# AASRC0_CFG register map
Vendor: Texas Instruments
Peripheral module from a debugger description file (folder J7ES).
Registers are 32-bit, access per field, reset values left out (the file's numbers can be read two ways) unless marked. A register's access mark holds for its fields unless they carry their own. Offsets are as the file gives them; lines under a group give offsets from that group; [hi:lo] are bit positions; {n}, {i} and the like mark numbered series; 'fields as' and 'values as' point back to an identical list; <NAME> marks a mode.

## AASRC0_CFG
0x00 AASRC_PID ro
  [31:0] REV — TI internal data. Identifies revision of peripheral.
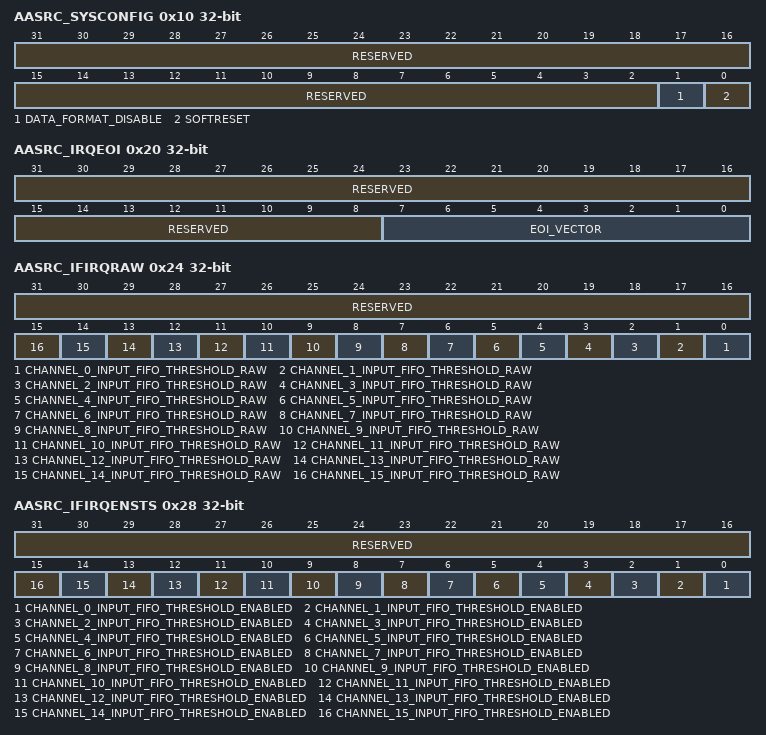
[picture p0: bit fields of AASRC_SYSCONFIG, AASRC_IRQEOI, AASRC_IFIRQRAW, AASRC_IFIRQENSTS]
0x10 AASRC_SYSCONFIG
  [31:2] RESERVED ro — Always read as 0
  [1] DATA_FORMAT_DISABLE rw — If this bit is enabled, data formatting needs to be done outside
  [0] SOFTRESET rw — Write 1'b1 for reset assertion and 1'b1 for reset deassertion.
0x20 AASRC_IRQEOI — The EOI register is used to re-trigger the pulse interrupt signal to ensure that any nested interrupt events are serviced. The software interrupt handler must write to the EOI register at the end of the current interrupt processing routine, so that new events can re-trigger the pulse interrupt signal again. For level interrupt signals the EOI register is not functional and must not be used.
  [31:8] RESERVED ro — Always read as 0
  [7:0] EOI_VECTOR rw — Number associated with the ipgenericirq for intr output. Write 0x0: Write to input_intr Write 0x1: Write to output_intr Write 0x2: Write to ingroup_intr Write 0x3: Write to outgroup_intr Write 0x4: Write to error_intr Any other write value is ignored. Always read as 0.
0x24 AASRC_IFIRQRAW access not given
  [31:16] RESERVED ro — Always read as 0
  [n] CHANNEL_{n}_INPUT_FIFO_THRESHOLD_RAW (n=0..15) — Channel {n} Input FIFO Threshold Interrupt. Read indicates raw status. This fires when the Input FIFO for this Channel is below the level set in the Configuration register. 0 = inactive. 1 = active. Writing 1 will set status. Writing 0 has no effect. (access RW1S)
0x28 AASRC_IFIRQENSTS access not given
  [31:16] RESERVED ro — Always read as 0
  [n] CHANNEL_{n}_INPUT_FIFO_THRESHOLD_ENABLED (n=0..15) — Channel {n} Input FIFO Threshold Interrupt. Read indicates enabled status. This fires when the Input FIFO for this Channel is below the level set in the Configuration register. 0 = inactive. 1 = active. Writing 1 will clear status. Writing 0 has no effect (access RW1C)
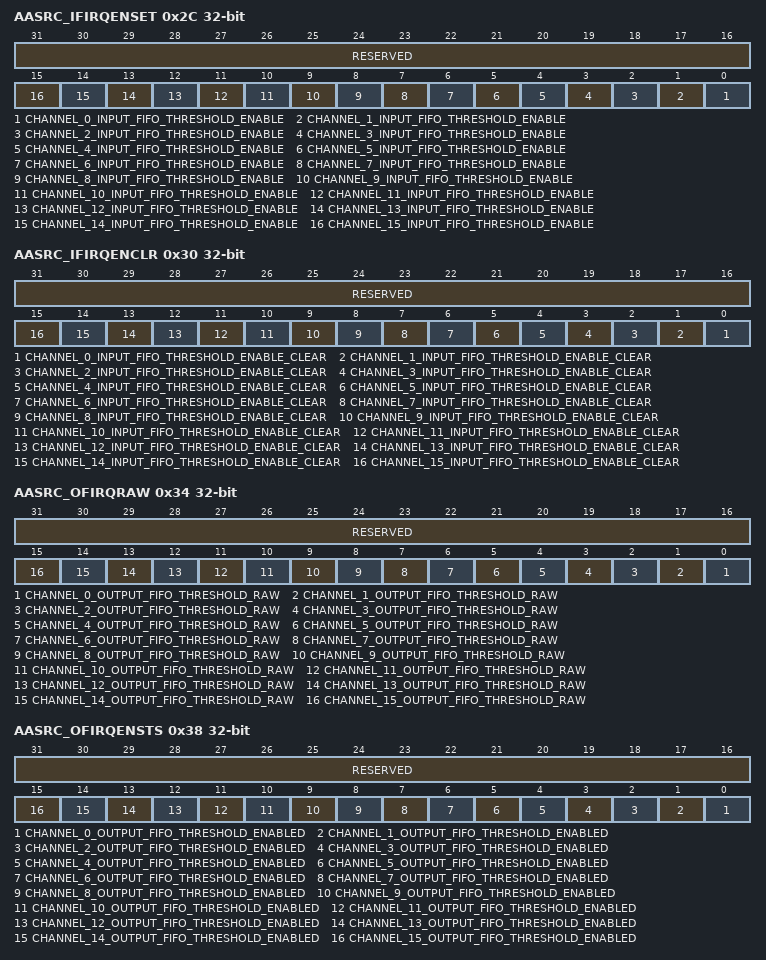
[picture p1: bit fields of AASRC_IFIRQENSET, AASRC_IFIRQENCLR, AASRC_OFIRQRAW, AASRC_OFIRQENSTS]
0x2C AASRC_IFIRQENSET access not given
  [31:16] RESERVED ro — Always read as 0
  [n] CHANNEL_{n}_INPUT_FIFO_THRESHOLD_ENABLE (n=0..15) — Channel {n} Input FIFO Threshold Interrupt. Read indicates interrupt enable. 0 = inactive. 1 = active. Writing 1 will set enable. Writing 0 has no effect (access RW1S)
0x30 AASRC_IFIRQENCLR access not given
  [31:16] RESERVED ro — Always read as 0
  [n] CHANNEL_{n}_INPUT_FIFO_THRESHOLD_ENABLE_CLEAR (n=0..15) — Channel {n} Input FIFO Threshold Interrupt. Read indicates interrupt enable. 0 = inactive. 1 = active. Writing 1 will clear enable. Writing 0 has no effect (access RW1C)
0x34 AASRC_OFIRQRAW access not given
  [31:16] RESERVED ro — Always read as 0
  [n] CHANNEL_{n}_OUTPUT_FIFO_THRESHOLD_RAW (n=0..15) — Channel {n} Output FIFO Threshold Interrupt. Read indicates raw status. This fires when the Output FIFO for this Channel is above the level set in the Configuration register. 0 = inactive. 1 = active. Writing 1 will set status. Writing 0 has no effect (access RW1S)
0x38 AASRC_OFIRQENSTS access not given
  [31:16] RESERVED ro — Always read as 0
  [n] CHANNEL_{n}_OUTPUT_FIFO_THRESHOLD_ENABLED (n=0..15) — Channel {n} Output FIFO Threshold Interrupt. Read indicates enabled status. This fires when the Output FIFO for this Channel is above the level set in the Configuration register. 0 = inactive. 1 = active. Writing 1 will clear status. Writing 0 has no effect. (access RW1C)
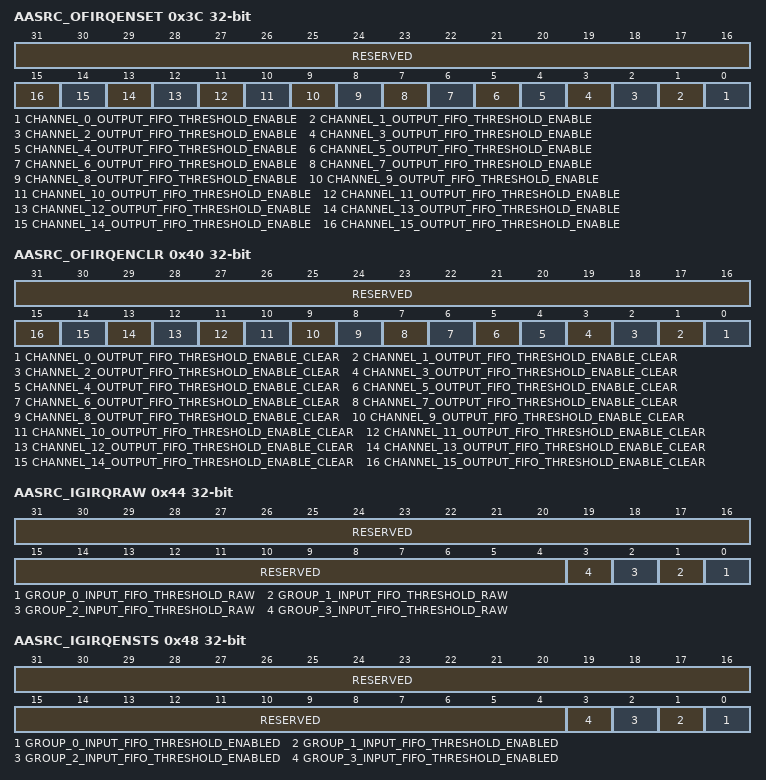
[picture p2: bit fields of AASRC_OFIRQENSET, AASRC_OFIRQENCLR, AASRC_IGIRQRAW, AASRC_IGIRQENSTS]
0x3C AASRC_OFIRQENSET access not given
  [31:16] RESERVED ro — Always read as 0
  [n] CHANNEL_{n}_OUTPUT_FIFO_THRESHOLD_ENABLE (n=0..15) — Channel {n} Output FIFO Threshold Interrupt. Read indicates interrupt enable. 0 = inactive. 1 = active. Writing 1 will set enable. Writing 0 has no effect. (access RW1S)
0x40 AASRC_OFIRQENCLR access not given
  [31:16] RESERVED ro — Always read as 0
  [n] CHANNEL_{n}_OUTPUT_FIFO_THRESHOLD_ENABLE_CLEAR (n=0..15) — Channel {n} Output FIFO Threshold Interrupt. Read indicates interrupt enable. 0 = inactive. 1 = active. Writing 1 will clear enable. Writing 0 has no effect. (access RW1C)
0x44 AASRC_IGIRQRAW access not given
  [31:4] RESERVED ro — Always read as 0
  [n] GROUP_{n}_INPUT_FIFO_THRESHOLD_RAW (n=0..3) — Group {n} Input FIFO Threshold Interrupt. Read indicates raw status. This fires when all the Input FIFOs for this Group is below the level set in the Configuration register. 0 = inactive. 1 = active. Writing 1 will set status. Writing 0 has no effect. (access RW1S)
0x48 AASRC_IGIRQENSTS access not given
  [31:4] RESERVED ro — Always read as 0
  [n] GROUP_{n}_INPUT_FIFO_THRESHOLD_ENABLED (n=0..3) — Group {n} Input FIFO Threshold Interrupt. Read indicates enabled status. This fires when all the Input FIFOs for this Group is below the level set in the Configuration register. 0 = inactive. 1 = active. Writing 1 will clear status. Writing 0 has no effect. (access RW1C)
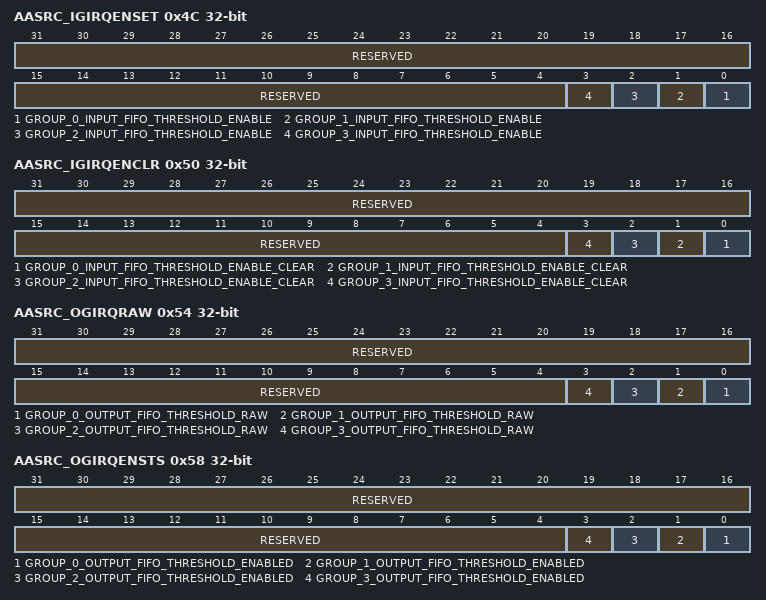
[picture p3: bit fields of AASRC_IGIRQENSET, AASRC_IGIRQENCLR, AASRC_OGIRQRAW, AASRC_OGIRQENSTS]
0x4C AASRC_IGIRQENSET access not given
  [31:4] RESERVED ro — Always read as 0
  [n] GROUP_{n}_INPUT_FIFO_THRESHOLD_ENABLE (n=0..3) — Group {n} Input FIFO Threshold Interrupt. Read indicates interrupt enable. 0 = inactive. 1 = active. Writing 1 will set enable. Writing 0 has no effect. (access RW1S)
0x50 AASRC_IGIRQENCLR access not given
  [31:4] RESERVED ro — Always read as 0
  [n] GROUP_{n}_INPUT_FIFO_THRESHOLD_ENABLE_CLEAR (n=0..3) — Group {n} Input FIFO Threshold Interrupt. Read indicates interrupt enable. 0 = inactive. 1 = active. Writing 1 will clear enable. Writing 0 has no effect. (access RW1C)
0x54 AASRC_OGIRQRAW access not given
  [31:4] RESERVED ro — Always read as 0
  [n] GROUP_{n}_OUTPUT_FIFO_THRESHOLD_RAW (n=0..3) — Group {n} Output FIFO Threshold Interrupt. Read indicates raw status. This fires when all the Output FIFOs for this Group is above the level set in the Configuration register. 0 = inactive. 1 = active. Writing 1 will set status. Writing 0 has no effect. (access RW1S)
0x58 AASRC_OGIRQENSTS access not given
  [31:4] RESERVED ro — Always read as 0
  [n] GROUP_{n}_OUTPUT_FIFO_THRESHOLD_ENABLED (n=0..3) — Group {n} Output FIFO Threshold Interrupt. Read indicates enabled status. This fires when all the Output FIFOs for this Group is above the level set in the Configuration register. 0 = inactive. 1 = active. Writing 1 will clear status. Writing 0 has no effect. (access RW1C)
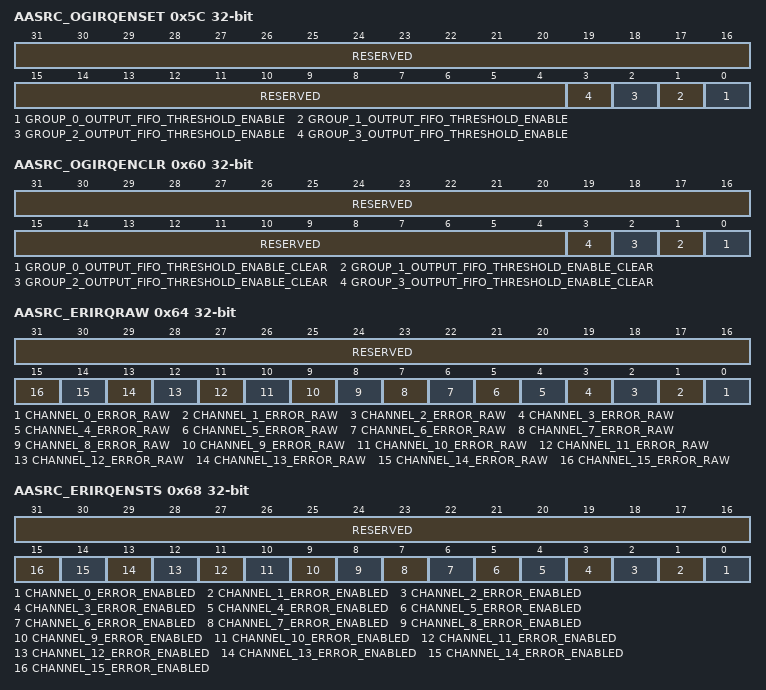
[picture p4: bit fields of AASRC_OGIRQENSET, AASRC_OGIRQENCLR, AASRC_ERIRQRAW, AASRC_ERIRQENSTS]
0x5C AASRC_OGIRQENSET access not given
  [31:4] RESERVED ro — Always read as 0
  [n] GROUP_{n}_OUTPUT_FIFO_THRESHOLD_ENABLE (n=0..3) — Group {n} Output FIFO Threshold Interrupt. Read indicates interrupt enable. 0 = inactive. 1 = active. Writing 1 will set enable. Writing 0 has no effect. (access RW1S)
0x60 AASRC_OGIRQENCLR access not given
  [31:4] RESERVED ro — Always read as 0
  [n] GROUP_{n}_OUTPUT_FIFO_THRESHOLD_ENABLE_CLEAR (n=0..3) — Group {n} Output FIFO Threshold Interrupt. Read indicates interrupt enable. 0 = inactive. 1 = active. Writing 1 will clear enable. Writing 0 has no effect. (access RW1C)
0x64 AASRC_ERIRQRAW access not given
  [31:16] RESERVED ro — Always read as 0
  [n] CHANNEL_{n}_ERROR_RAW (n=0..15) — Channel {n} FIFOs Error Interrupt Read indicates raw status. This fires when the FIFOs for this Channel isUnderflowed/Overflowed 0 = inactive 1 = active Writing 1 will set status Writing 0 has no effect (access RW1S)
0x68 AASRC_ERIRQENSTS access not given
  [31:16] RESERVED ro — Always read as 0
  [n] CHANNEL_{n}_ERROR_ENABLED (n=0..15) — Channel {n} FIFOs Error Interrupt Read indicates enabled status. This fires when the FIFOs for this Channel isUnderflowed/Overflowed 0 = inactive 1 = active Writing 1 will clear status Writing 0 has no effect (access RW1C)
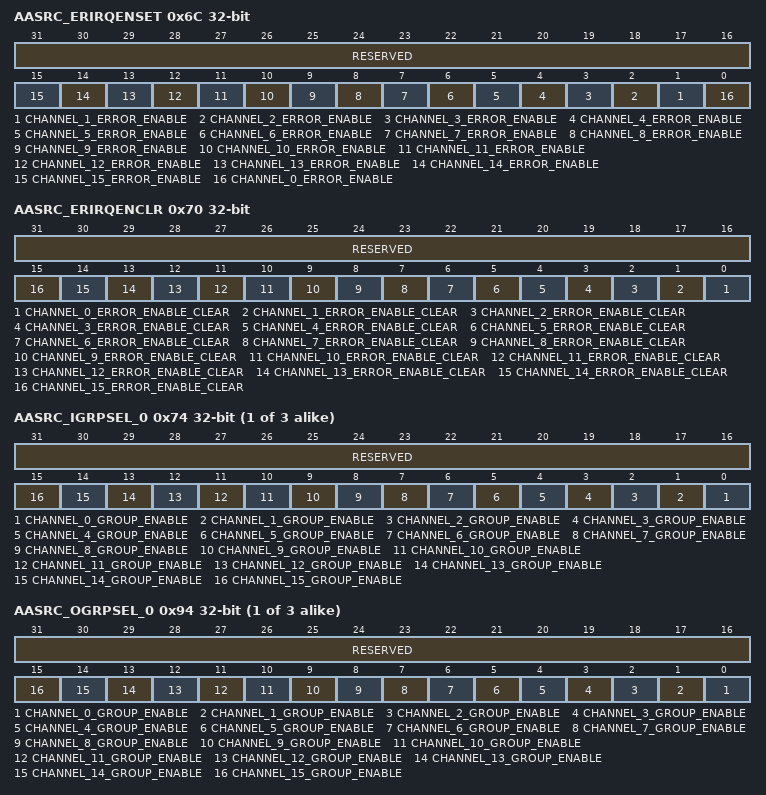
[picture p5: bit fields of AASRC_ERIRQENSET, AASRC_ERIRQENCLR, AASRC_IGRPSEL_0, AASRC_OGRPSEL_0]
0x6C AASRC_ERIRQENSET access not given
  [31:16] RESERVED ro — Always read as 0
  [n] CHANNEL_{n}_ERROR_ENABLE (n=1..15) — Channel {n} FIFOs Error Interrupt Read indicates interrupt enable. 0 = inactive 1 = active Writing 1 will set enable Writing 0 has no effect (access RW1S)
  [0] CHANNEL_0_ERROR_ENABLE — Channel 10 FIFOs Error Interrupt Read indicates interrupt enable. 0 = inactive 1 = active Writing 1 will set enable Writing 0 has no effect (access RW1S)
0x70 AASRC_ERIRQENCLR access not given
  [31:16] RESERVED ro — Always read as 0
  [n] CHANNEL_{n}_ERROR_ENABLE_CLEAR (n=0..15) — Channel {n} FIFOs Error Interrupt Read indicates interrupt enable. 0 = inactive 1 = active Writing 1 will clear enable Writing 0 has no effect (access RW1C)
{0x74+4i} AASRC_IGRPSEL_{i} (i=0..2)
  [31:16] RESERVED ro — Always read as 0
  [n] CHANNEL_{n}_GROUP_ENABLE rw (n=0..15) — Input Channel {n} Group Enable indicates if the Input Channel is part of the group0 for the group settings and interrupt event generation. If this bit is set then the group event and interrupt will not fire until the threshold condition for this Input Channel is met. 0 = inactive 1 = active Writing 1 will enable Writing 0 will disable
{0x94+4i} AASRC_OGRPSEL_{i} (i=0..2)
  [31:16] RESERVED ro — Always read as 0
  [n] CHANNEL_{n}_GROUP_ENABLE rw (n=0..15) — Output Channel {n} Group Enable indicates if the Output Channel is part of the group0 for the group settings and interrupt event generation. If this bit is set then the group event and interrupt will not fire until the threshold condition for this Output Channel is met. 0 = inactive 1 = active Writing 1 will enable Writing 0 will disable
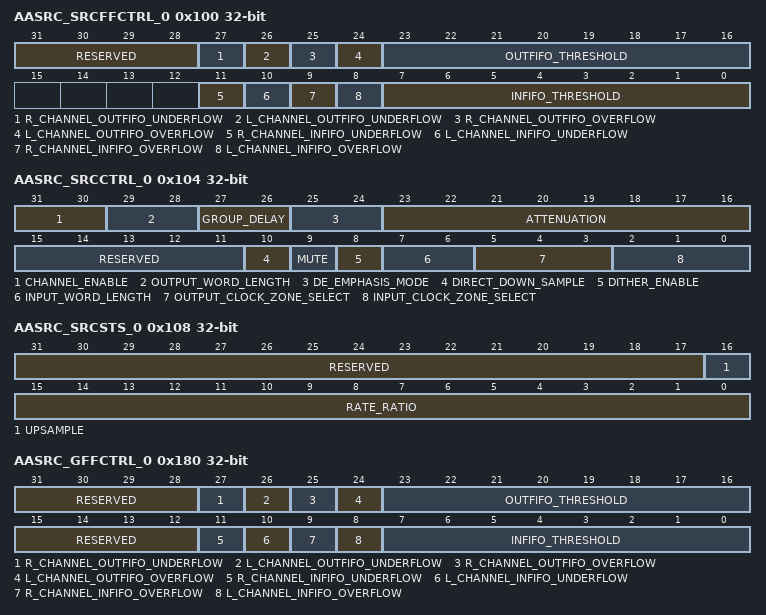
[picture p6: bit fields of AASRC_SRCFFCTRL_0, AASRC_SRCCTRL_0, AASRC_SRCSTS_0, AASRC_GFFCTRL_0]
0x100 AASRC_SRCFFCTRL_0
  [31:28] RESERVED ro — Always read as 0
  [27] R_CHANNEL_OUTFIFO_UNDERFLOW ro — This signal is set to 1 when Right Channel OUTFIFO for SRC0 is underflowed
  [26] L_CHANNEL_OUTFIFO_UNDERFLOW ro — This signal is set to 1 when Left Channel OUTFIFO for SRC0 is underflowed
  [25] R_CHANNEL_OUTFIFO_OVERFLOW ro — This signal is set to 1 when Right Channel OUTFIFO for SRC0 is overflowed
  [24] L_CHANNEL_OUTFIFO_OVERFLOW ro — This signal is set to 1 when Left Channel OUTFIFO for SRC0 is overflowed
  [23:16] OUTFIFO_THRESHOLD rw — This is the number of samples that must be available for the interrupt and SRC0 OUTFIFOs event to fire. 1-32: 1-32 samples
  [11] R_CHANNEL_INFIFO_UNDERFLOW ro — This signal is set to 1 when Right Channel INFIFO for SRC0 is underflowed
  [10] L_CHANNEL_INFIFO_UNDERFLOW ro — This signal is set to 1 when Left Channel INFIFO for SRC0 is underflowed
  [9] R_CHANNEL_INFIFO_OVERFLOW ro — This signal is set to 1 when Right Channel INFIFO for SRC0 is overflowed
  [8] L_CHANNEL_INFIFO_OVERFLOW ro — This signal is set to 1 when Left Channel INFIFO for SRC0 is overflowed
  [7:0] INFIFO_THRESHOLD rw — This is the number of samples that must be available for the interrupt and SRC0 INFIFOs event to fire. 1-32: 1-32 samples
0x104 AASRC_SRCCTRL_0
  [31:30] CHANNEL_ENABLE rw — Setting this enables the Channels of SRC0. The output FIFOs for the stream must be enabled before the input FIFOs. 00: No channel enabled 01: Only Right Channel enabled 10: Only Left Channel enabled 11: Both channels enabled Clearing this register will clear the data path.
  [29:28] OUTPUT_WORD_LENGTH rw — These bits select the word length for the SRC0 output data. The word length reduction is performed by utilizing triangular PDF dithering. 0: 24 Bits (Default) 1: 20 Bits 2: 18 Bits 3: 16 Bits
  [27:26] GROUP_DELAY rw — These bits select the interpolation filter group delay by configuring the number of samples which are pre-buffered prior to the re-sampler function. 0: 64 Samples (Default) 1: 32 Samples 2: 16 Samples 3: 8 Samples
  [25:24] DE_EMPHASIS_MODE rw — These bits are utilized to enable or disable the digital de-emphasis filter manually. The de-emphasis filter is intended to process 50/15 s pre-emphasized audio material at the following input sampling rates. 0: De-Emphasis Disabled (Default) 1: De-Emphasis Enabled for fS = 48kHz 2: De-Emphasis Enabled for fS = 44.1kHz 3: De-Emphasis Enabled for fS = 32kHz
  [23:16] ATTENUATION rw — These bits are utilized to configure the SRC digital output attenuation for the stream Output Attenuation (dB) = N 0.5, where N = Attenuation[7:0]DEC.
  [15:11] RESERVED ro — Always read as 0
  [10] DIRECT_DOWN_SAMPLE rw — This bit selects the mode of the decimation function, either true decimation filter or direct down-sampling without filtering. DDN Decimation Function 0 Decimation Filter (Default) 1 Direct Down Sampling Note: Direct down-sampling should only be used when the output sampling rate is higher than the input sampling rate. When the output sampling rate is equal to or lower than the input sampling rate, the Decimation Filter must be used in order to avoid aliasing. Direct down conversion might have negative effect on SNR.
  [9] MUTE rw — This bit enables or disables the SRC output soft mute function. 0: Mute Disabled (Default) 1: Mute enabled; output data set to all zeros.
  [8] DITHER_ENABLE rw — This bit enables or disables the SRC filter s dithering. 0: Dithering Disabled (Default) 1: Dithering enabled
  [7:6] INPUT_WORD_LENGTH rw — These bits select the word length for the SRC0 input data. 0: 24 Bits (Default) 1: 20 Bits 2: 18 Bits 3: 16 Bits
  [5:3] OUTPUT_CLOCK_ZONE_SELECT rw — This selects the output clock zone for the stream0. It can select between the 4 external audio clock zones. Based on this number rate and stamp is passed to the Stream0 Sample rate converter from respective clock recovery loop. 00: This selects the Clock Recovery loop 0. 01: This selects the Clock Recovery loop 1. 10: This selects the Clock Recovery loop 2. 11: This selects the Clock Recovery loop 3. In this SoC other values are not valid.
  [2:0] INPUT_CLOCK_ZONE_SELECT rw — This selects the input clock zone for the stream0. It can select between the 4 external audio clock zones. Based on this number rate and stamp is passed to the Stream0 Sample rate converter from respective clock recovery loop. 000: This selects the Clock Recovery loop 0. 001: This selects the Clock Recovery loop 1. 010: This selects the Clock Recovery loop 2. 011: This selects the Clock Recovery loop 3. In this SoC other values are not valid.
0x108 AASRC_SRCSTS_0 ro
  [31:17] RESERVED — Always read as 0
  [16] UPSAMPLE — This signal becomes high when Output sampling rate is greater than Input sampling ratio
  [15:0] RATE_RATIO — Input to Output sampling ratio for SRC0
0x180 AASRC_GFFCTRL_0
  [31:28] RESERVED ro — Always read as 0
  [27] R_CHANNEL_OUTFIFO_UNDERFLOW ro — This signal is set to 1 when any of the Right Channel OUTFIFO for Group0 SRCs is underflowed
  [26] L_CHANNEL_OUTFIFO_UNDERFLOW ro — This signal is set to 1 when any of the Left Channel OUTFIFO for Group0 SRCs is underflowed
  [25] R_CHANNEL_OUTFIFO_OVERFLOW ro — This signal is set to 1 when any of the Right Channel OUTFIFO for Group0 SRCs is overflowed
  [24] L_CHANNEL_OUTFIFO_OVERFLOW ro — This signal is set to 1 when any of the Left Channel OUTFIFO for Group0 SRCs is overflowed
  [23:16] OUTFIFO_THRESHOLD rw — This is the number of samples that must be available for the interrupt and Group0 SRCs OUTFIFOs event to fire.
  [15:12] RESERVED ro — Always read as 0
  [11] R_CHANNEL_INFIFO_UNDERFLOW ro — This signal is set to 1 when any of the Right Channel INFIFO for Group0 SRCs is underflowed
  [10] L_CHANNEL_INFIFO_UNDERFLOW ro — This signal is set to 1 when any of the Left Channel INFIFO for Group0 SRCs is underflowed
  [9] R_CHANNEL_INFIFO_OVERFLOW ro — This signal is set to 1 when any of the Right Channel INFIFO for Group0 SRCs is overflowed
  [8] L_CHANNEL_INFIFO_OVERFLOW ro — This signal is set to 1 when any of the Left Channel INFIFO for Group0 SRCs is overflowed
  [7:0] INFIFO_THRESHOLD rw — This is the number of samples that must be available for the interrupt and Group0 SRCs INFIFOs event to fire.
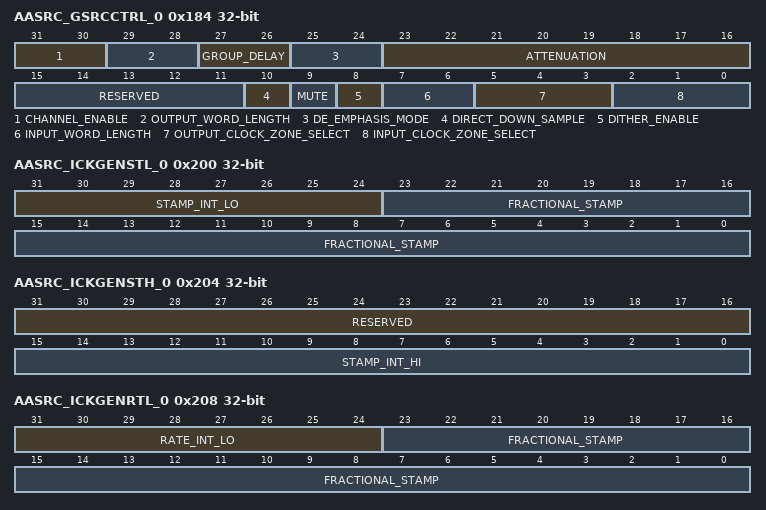
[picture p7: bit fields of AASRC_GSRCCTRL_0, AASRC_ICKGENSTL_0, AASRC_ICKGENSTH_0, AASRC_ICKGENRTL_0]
0x184 AASRC_GSRCCTRL_0
  [31:30] CHANNEL_ENABLE rw — Setting this enables the Channels of Group0 SRCs. The output FIFOs for the stream must be enabled before the input FIFOs. 00: No channel enabled 01: Only Right Channel enabled 10: Only Left Channel enabled 11: Both channels enabled Clearing this register will clear the data path
  [29:28] OUTPUT_WORD_LENGTH rw — These bits select the word length for the Group0 SRC output data. The word length reduction is performed by utilizing triangular PDF dithering. 0: 24 Bits (Default) 1: 20 Bits 2: 18 Bits 3: 16 Bits
  [27:26] GROUP_DELAY rw — These bits select the interpolation filter group delay by configuring the number of samples which are pre-buffered prior to the re-sampler function. 0: 64 Samples (Default) 1: 32 Samples 2: 16 Samples 3: 8 Samples
  [25:24] DE_EMPHASIS_MODE rw — These bits are utilized to enable or disable the digital de-emphasis filter manually. The de-emphasis filter is intended to process 50/15 s pre-emphasized audio material at the following input sampling rates. 0: De-Emphasis Disabled (Default) 1: De-Emphasis Enabled for fS = 48kHz 2: De-Emphasis Enabled for fS = 44.1kHz 3: De-Emphasis Enabled for fS = 32kHz
  [23:16] ATTENUATION rw — These bits are utilized to configure the Group0 SRC digital output attenuation for the stream Output Attenuation (dB) = N 0.5, where N = Attenuation[7:0]DEC.
  [15:11] RESERVED ro — Always read as 0
  [10] DIRECT_DOWN_SAMPLE rw — This bit selects the mode of the decimation function, either true decimation filter or direct down-sampling without filtering. DDN Decimation Function 0 Decimation Filter (Default) 1 Direct Down Sampling Note: Direct down-sampling should only be used when the output sampling rate is higher than the input sampling rate. When the output sampling rate is equal to or lower than the input sampling rate, the Decimation Filter must be used in order to avoid aliasing. Direct down conversion might have negative effect on SNR.
  [9] MUTE rw — This bit enables or disables the Group0 SRC output soft mute function. 0: Mute Disabled (Default) 1: Mute enabled; output data set to all zeros.
  [8] DITHER_ENABLE rw — This bit enables or disables the Group0 SRC filter s dithering. 0: Dithering Disabled (Default) 1: Dithering enabled;
  [7:6] INPUT_WORD_LENGTH rw — These bits select the word length for the SRC0 input data. 0: 24 Bits (Default) 1: 20 Bits 2: 18 Bits 3: 16 Bits
  [5:3] OUTPUT_CLOCK_ZONE_SELECT rw — This selects the output clock zone for the Group0 SRCs. It can select between the 4 external audio clock zones. Based on this number rate and stamp is passed to the Stream0 Sample rate converter from respective clock recovery loop. 00: This selects the Clock Recovery loop 0. 01: This selects the Clock Recovery loop 1. 10: This selects the Clock Recovery loop 2. 11: This selects the Clock Recovery loop 3. In this SoC other values are not valid.
  [2:0] INPUT_CLOCK_ZONE_SELECT rw — This selects the input clock zone for the Group0 SRCs. It can select between the 4 external audio clock zones. Based on this number rate and stamp is passed to the Stream0 Sample rate converter from respective clock recovery loop. 000: This selects the Clock Recovery loop 0. 001: This selects the Clock Recovery loop 1. 010: This selects the Clock Recovery loop 2. 011: This selects the Clock Recovery loop 3. In this SoC other values are not valid.
0x200 AASRC_ICKGENSTL_0 rw — The functions controlled by this register are not supported in this family of devices.
  [31:24] STAMP_INT_LO — This is the lower 8 bits of the integer multiple of the next timestamp for the clock source. This register will be updated by adding the Clock Generator Rate to the Stamp value whenever the Free Running Counter passes the Stamp value.
  [23:0] FRACTIONAL_STAMP — This is the fractional portion of the next timestamp for the clock source. This register will be updated by adding the Clock Generator Rate to the Stamp value whenever the Free Running Counter passes the Stamp value.
0x204 AASRC_ICKGENSTH_0 — The functions controlled by this register are not supported in this family of devices.
  [31:16] RESERVED ro — Always read as 0
  [15:0] STAMP_INT_HI rw — This is the upper 16 bits of the integer multiple of the next timestamp for the clock source. This register will be updated by adding the Clock Generator Rate to the Stamp value whenever the Free Running Counter passes the Stamp value.
0x208 AASRC_ICKGENRTL_0 rw — The functions controlled by this register are not supported in this family of devices.
  [31:24] RATE_INT_LO — This is the lower 8 bits of the integer multiple of the rate for the clock source. This register will be added with the Clock Generator Stamp to update the Stamp value whenever the Free Running Counter passes the Stamp value.
  [23:0] FRACTIONAL_STAMP — This is the fractional portion of the rate for the clock source.
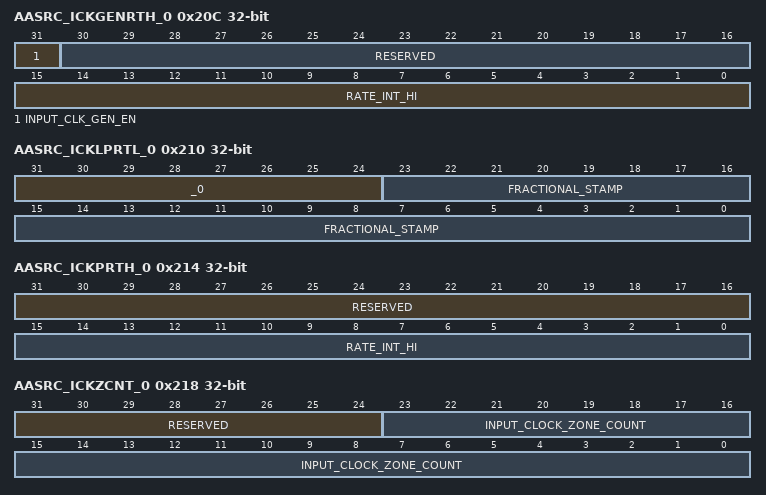
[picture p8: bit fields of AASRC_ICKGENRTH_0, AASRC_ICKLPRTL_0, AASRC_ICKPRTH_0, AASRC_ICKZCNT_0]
0x20C AASRC_ICKGENRTH_0 — The functions controlled by this register are not supported in this family of devices.
  [31] INPUT_CLK_GEN_EN rw — This signal enables the Input Clock Generator 0 1: Enable 0: Disable
  [30:16] RESERVED ro — Always read as 0
  [15:0] RATE_INT_HI rw — This is the lower 8 bits of the integer multiple of the rate for the clock source. This register will be added with the Clock Generator Stamp to update the Stamp value whenever the Free Running Counter passes the Stamp value.
0x210 AASRC_ICKLPRTL_0 ro — The functions controlled by this register are not supported in this family of devices.
  [31:24] _0 — This is the lower 8 bits of the integer multiple of the rate for the intput clock recovery loop 0.
  [23:0] FRACTIONAL_STAMP — This is the fractional portion of the rate for the intput clock recovery loop 0
0x214 AASRC_ICKPRTH_0 ro — The functions controlled by this register are not supported in this family of devices.
  [31:16] RESERVED — Always read as 0
  [15:0] RATE_INT_HI — This is the upper 16 bits of the integer multiple of the rate for the intput clock recovery loop 0.
0x218 AASRC_ICKZCNT_0 — The functions controlled by this register are not supported in this family of devices.
  [31:24] RESERVED ro — Always read as 0
  [23:0] INPUT_CLOCK_ZONE_COUNT rw — This gives the value of free running counter at every posedge of sync signal.
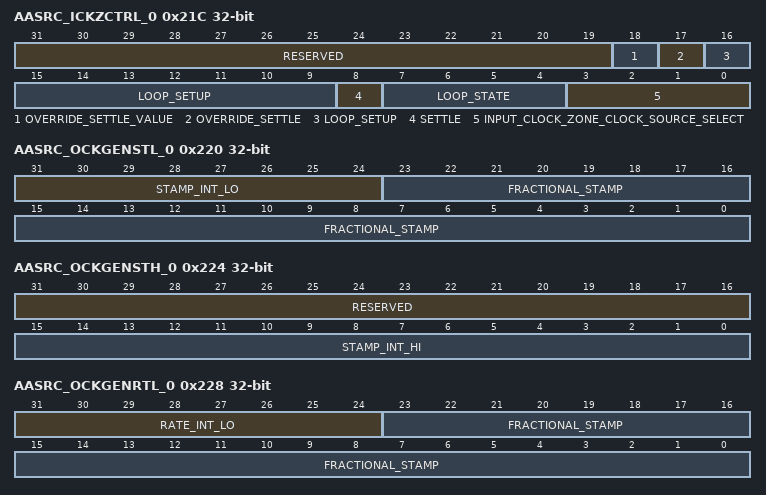
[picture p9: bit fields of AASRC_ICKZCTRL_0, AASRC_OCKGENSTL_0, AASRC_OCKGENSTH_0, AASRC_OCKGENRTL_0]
0x21C AASRC_ICKZCTRL_0
  [31:19] RESERVED ro — Always read as 0
  [18] OVERRIDE_SETTLE_VALUE rw — Value written to this field will be used as settle if override settle signal is set.
  [17] OVERRIDE_SETTLE rw — This signal override the settle of input clock zone 0 clock recovery loop. 1'b1: value written to override settle value will be used. 1'b0: settle from clock recovery will be used.
  [16:9] LOOP_SETUP rw — This is the setting for input clock recovery loop for zone 0 8 h00: Fast loop 8 h40: Medium1 loop 8 h80: Medium2 loop 8 hC0: Slow loop
  [8] SETTLE ro — This signals sets to 1 when clock recovery loop is settled
  [7:4] LOOP_STATE ro — Loop debug State
  [3:0] INPUT_CLOCK_ZONE_CLOCK_SOURCE_SELECT rw — This selects the 8x1 and 2x1 mux structure for input clock zone 0. 1xxx: Clock comes from input clock gen 0 0000-0111: Selects rxsync signal from 0-7
0x220 AASRC_OCKGENSTL_0 rw — The functions controlled by this register are not supported in this family of devices.
  fields as AASRC_ICKGENSTL_0
0x224 AASRC_OCKGENSTH_0 — The functions controlled by this register are not supported in this family of devices.
  fields as AASRC_ICKGENSTH_0
0x228 AASRC_OCKGENRTL_0 rw — The functions controlled by this register are not supported in this family of devices.
  fields as AASRC_ICKGENRTL_0
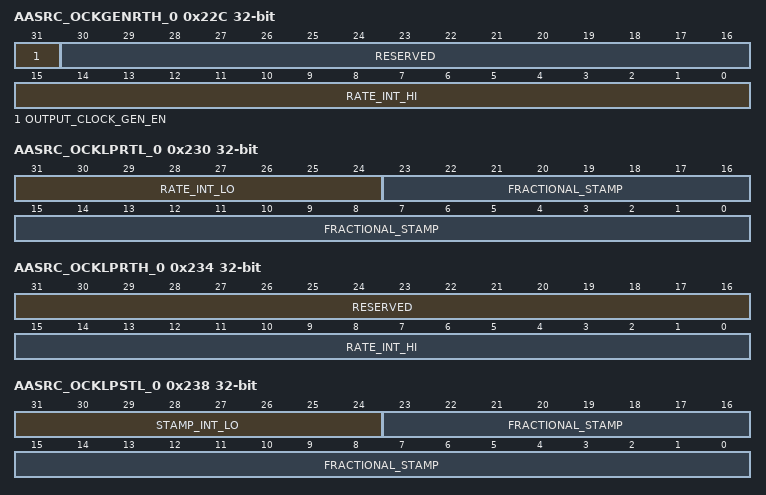
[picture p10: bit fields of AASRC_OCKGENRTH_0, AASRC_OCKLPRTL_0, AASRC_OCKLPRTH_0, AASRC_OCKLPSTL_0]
0x22C AASRC_OCKGENRTH_0 — The functions controlled by this register are not supported in this family of devices.
  [31] OUTPUT_CLOCK_GEN_EN rw — This signal enables the Output Clock Generator 0 1: Enable 0: Disable
  [30:16] RESERVED ro — Always read as 0
  [15:0] RATE_INT_HI rw — This is the lower 8 bits of the integer multiple of the rate for the clock source. This register will be added with the Clock Generator Stamp to update the Stamp value whenever the Free Running Counter passes the Stamp value.
0x230 AASRC_OCKLPRTL_0 ro — The functions controlled by this register are not supported in this family of devices.
  [31:24] RATE_INT_LO — This is the lower 8 bits of the integer multiple of the rate for the outtput clock recovery loop 0.
  [23:0] FRACTIONAL_STAMP — This is the fractional portion of the rate for the outtput clock recovery loop 0.
0x234 AASRC_OCKLPRTH_0 ro — The functions controlled by this register are not supported in this family of devices.
  [31:16] RESERVED — Always read as 0
  [15:0] RATE_INT_HI — This is the Upper 16 bits of the integer multiple of the rate for the outtput clock recovery loop 0.
0x238 AASRC_OCKLPSTL_0 ro — The functions controlled by this register are not supported in this family of devices.
  [31:24] STAMP_INT_LO — This is the lower 8 bits of the integer multiple of the next timestamp for the clock source. This register will be updated when output fifo event occurs
  [23:0] FRACTIONAL_STAMP — This is the fractional portion of the next timestamp for the clock source. This register will be updated when output fifo event occurs
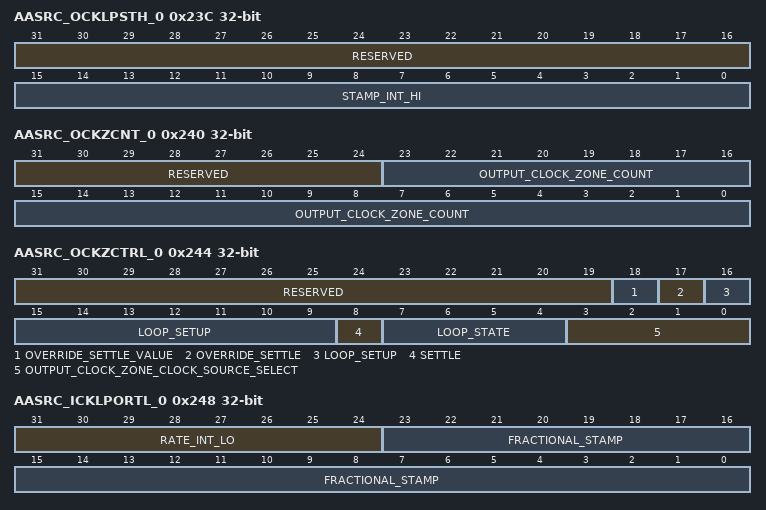
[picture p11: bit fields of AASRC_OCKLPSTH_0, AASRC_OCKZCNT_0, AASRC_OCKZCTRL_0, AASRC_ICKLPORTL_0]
0x23C AASRC_OCKLPSTH_0 ro — The functions controlled by this register are not supported in this family of devices.
  [31:16] RESERVED — Always read as 0
  [15:0] STAMP_INT_HI — This is the upper 16 bits of the integer multiple of the next timestamp for the clock recovery loop. This register will be updated when output fifo event occurs
0x240 AASRC_OCKZCNT_0 — The functions controlled by this register are not supported in this family of devices.
  [31:24] RESERVED ro — Always read as 0
  [23:0] OUTPUT_CLOCK_ZONE_COUNT rw — This gives the value of free running counter at every posedge of sync signal
0x244 AASRC_OCKZCTRL_0
  [31:19] RESERVED ro — Always read as 0
  [18] OVERRIDE_SETTLE_VALUE rw — Value written to this field will be used as settle if override settle signal is set.
  [17] OVERRIDE_SETTLE rw — This signal override the settle of output clock zone 0 clock recovery loop. 1'b1: value written to override settle value will be used. 1'b0: settle from clock recovery will be used.
  [16:9] LOOP_SETUP rw — This is the setting for input clock recovery loop for zone 0 8 h00: Fast loop 8 h40: Medium1 loop 8 h80: Medium2 loop 8 hC0: Slow loop
  [8] SETTLE ro — This signals sets to 1 when clock recovery loop is settled
  [7:4] LOOP_STATE ro — Loop debug state
  [3:0] OUTPUT_CLOCK_ZONE_CLOCK_SOURCE_SELECT rw — This selects the 8x1 and 2x1 mux structure for output clock zone 0. 1xxx: Clock comes from output clock gen 0 0000-0111: Selects txsync signal from 0-7
0x248 AASRC_ICKLPORTL_0 rw — The functions controlled by this register are not supported in this family of devices.
  [31:24] RATE_INT_LO — This is the lower 8 bits of the integer multiple of the rate for the override clock recovery loop 0.
  [23:0] FRACTIONAL_STAMP — This is the fractional portion of the rate for the override clock recovery loop 0.
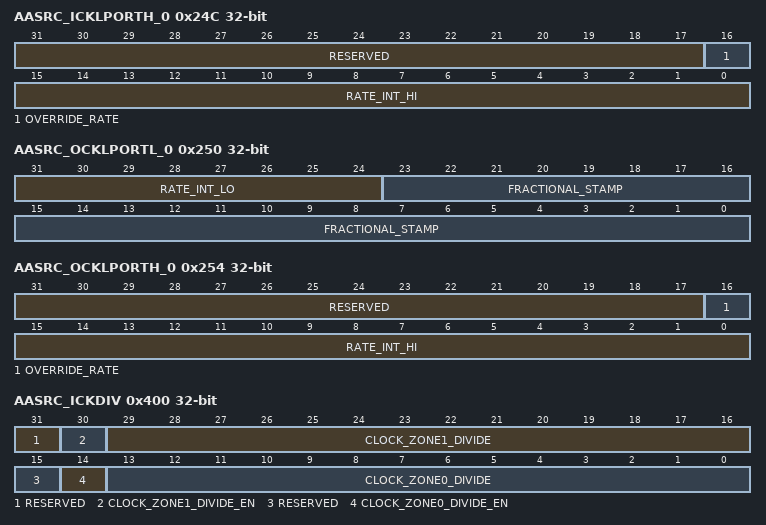
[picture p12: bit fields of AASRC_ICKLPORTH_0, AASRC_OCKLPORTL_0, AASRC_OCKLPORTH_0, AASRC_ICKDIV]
0x24C AASRC_ICKLPORTH_0 — The functions controlled by this register are not supported in this family of devices.
  [31:17] RESERVED ro — Always read as 0
  [16] OVERRIDE_RATE rw — This is the upper 16 bits of the integer multiple of the rate for the override clock recovery loop 0.
  [15:0] RATE_INT_HI rw — This is the upper 16 bits of the integer multiple of the rate for the override clock recovery loop 0.
0x250 AASRC_OCKLPORTL_0 rw — The functions controlled by this register are not supported in this family of devices.
  [31:24] RATE_INT_LO — This is the lower 8 bits of the integer multiple of the rate for the output override clock recovery loop 0.
  [23:0] FRACTIONAL_STAMP — This is the fractional portion of the rate for the output override clock recovery loop 0.
0x254 AASRC_OCKLPORTH_0 — The functions controlled by this register are not supported in this family of devices.
  [31:17] RESERVED ro — Always read as 0
  [16] OVERRIDE_RATE rw — This is the upper 16 bits of the integer multiple of the rate for the output override clock recovery loop 0.
  [15:0] RATE_INT_HI rw — This is the Upper 16 bits of the integer multiple of the rate for the output override clock recovery loop 0.
0x400 AASRC_ICKDIV
  [31] RESERVED ro — Always read as 0
  [30] CLOCK_ZONE1_DIVIDE_EN rw — Clock zone 1 divider enable. 1'b1:Divider logic enable. 1'b0:Divider logic disable.
  [29:16] CLOCK_ZONE1_DIVIDE rw — This is the setting for input clock zone1 sync signal division value
  [15] RESERVED ro — Always read as 0
  [14] CLOCK_ZONE0_DIVIDE_EN rw — Clock zone 0 divider enable. 1'b1:Divider logic enable. 1'b0:Divider logic disable.
  [13:0] CLOCK_ZONE0_DIVIDE rw — This is the setting for input clock zone0 sync signal division value
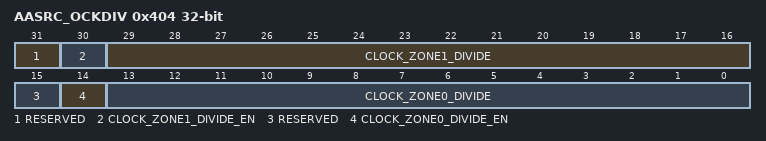
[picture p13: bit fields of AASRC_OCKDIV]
0x404 AASRC_OCKDIV
  [31] RESERVED ro — Always read as 0
  [30] CLOCK_ZONE1_DIVIDE_EN rw — Clock zone 1 divider enable. 1'b1:Divider logic enable. 1'b0:Divider logic disable.
  [29:16] CLOCK_ZONE1_DIVIDE rw — This is the setting for output clock zone1 sync signal division value
  [15] RESERVED ro — Always read as 0
  [14] CLOCK_ZONE0_DIVIDE_EN rw — Clock zone 0 divider enable. 1'b1:Divider logic enable. 1'b0:Divider logic disable.
  [13:0] CLOCK_ZONE0_DIVIDE rw — This is the setting for output clock zone0 sync signal division value
